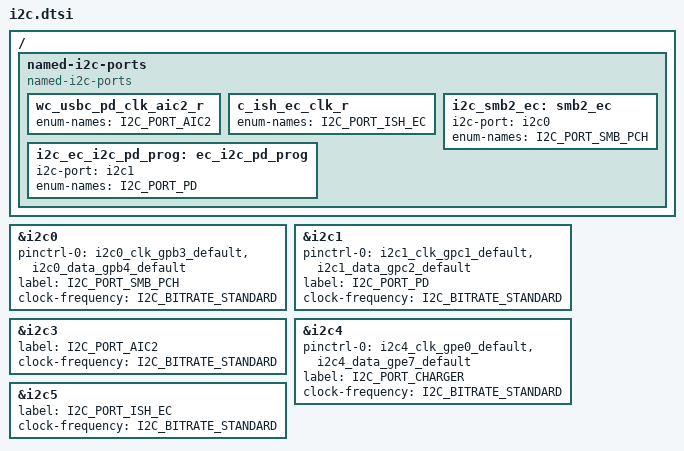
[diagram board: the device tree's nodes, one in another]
/* Copyright 2024 The ChromiumOS Authors
 * Use of this source code is governed by a BSD-style license that can be
 * found in the LICENSE file.
 */

/ {
	named-i2c-ports {
		compatible = "named-i2c-ports";

		wc_usbc_pd_clk_aic2_r {
			enum-names = "I2C_PORT_AIC2";
		};

		c_ish_ec_clk_r {
			enum-names = "I2C_PORT_ISH_EC";
		};

		i2c_smb2_ec: smb2_ec {
			i2c-port = <&i2c0>;
			enum-names = "I2C_PORT_SMB_PCH";
		};

		i2c_ec_i2c_pd_prog: ec_i2c_pd_prog {
			i2c-port = <&i2c1>;
			enum-names = "I2C_PORT_PD";
		};
	};
};

&i2c0 {
	pinctrl-0 = <&i2c0_clk_gpb3_default
		&i2c0_data_gpb4_default>;
	pinctrl-names = "default";

	label = "I2C_PORT_SMB_PCH";
	clock-frequency = <I2C_BITRATE_STANDARD>;
};

&i2c1 {
	pinctrl-0 = <&i2c1_clk_gpc1_default
		     &i2c1_data_gpc2_default>;
	pinctrl-names = "default";

	label = "I2C_PORT_PD";
	clock-frequency = <I2C_BITRATE_STANDARD>;
};


&i2c3 {
	label = "I2C_PORT_AIC2";
	clock-frequency = <I2C_BITRATE_STANDARD>;
};

&i2c4 {
	pinctrl-0 = <&i2c4_clk_gpe0_default
		     &i2c4_data_gpe7_default>;
	pinctrl-names = "default";

	label = "I2C_PORT_CHARGER";
	clock-frequency = <I2C_BITRATE_STANDARD>;
};

&i2c5 {
	label = "I2C_PORT_ISH_EC";
	clock-frequency = <I2C_BITRATE_STANDARD>;
};
